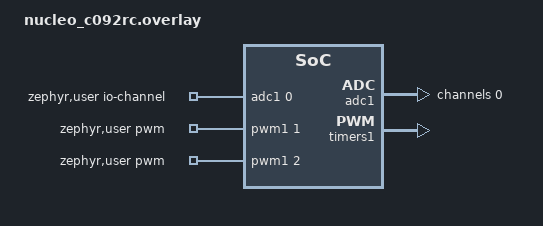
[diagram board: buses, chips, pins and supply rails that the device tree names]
/*
 * Overlay for nucleo_c092rc:
 *   A0  -> PA0  -> ADC1 channel 0   (potentiometer)
 *   D9  -> PA8  -> TIM1_CH1         (reverse PWM)
 *   D8  -> PA9  -> TIM1_CH2         (forward PWM)
 */

/ {
	zephyr,user {
		/* ADC channel for potentiometer */
		io-channels = <&adc1 0>;

		/*
		 * Two PWM outputs:
		 *   pwm channel 1 -> D9 (PA8)
		 *   pwm channel 2 -> D8 (PA9)
		 *
		 * 50 us period = 20 kHz
		 */
		pwms =
			<&pwm1 1 PWM_USEC(50) PWM_POLARITY_NORMAL>,
			<&pwm1 2 PWM_USEC(50) PWM_POLARITY_NORMAL>;
	};
};

&adc1 {
	#address-cells = <1>;
	#size-cells = <0>;
	status = "okay";

	channel@0 {
		reg = <0>;
		zephyr,gain = "ADC_GAIN_1";
		zephyr,reference = "ADC_REF_INTERNAL";
		zephyr,acquisition-time = <ADC_ACQ_TIME_DEFAULT>;
		zephyr,resolution = <12>;
	};
};

/*
 * TIM1:
 *   CH1 -> PA8  (D9)
 *   CH2 -> PA9  (D8)
 */
&timers1 {
	status = "okay";
	st,prescaler = <0>;

	pwm1: pwm {
		status = "okay";

		pinctrl-0 = <
			&tim1_ch1_pa8
			&tim1_ch2_pa9
		>;

		pinctrl-names = "default";
	};
};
